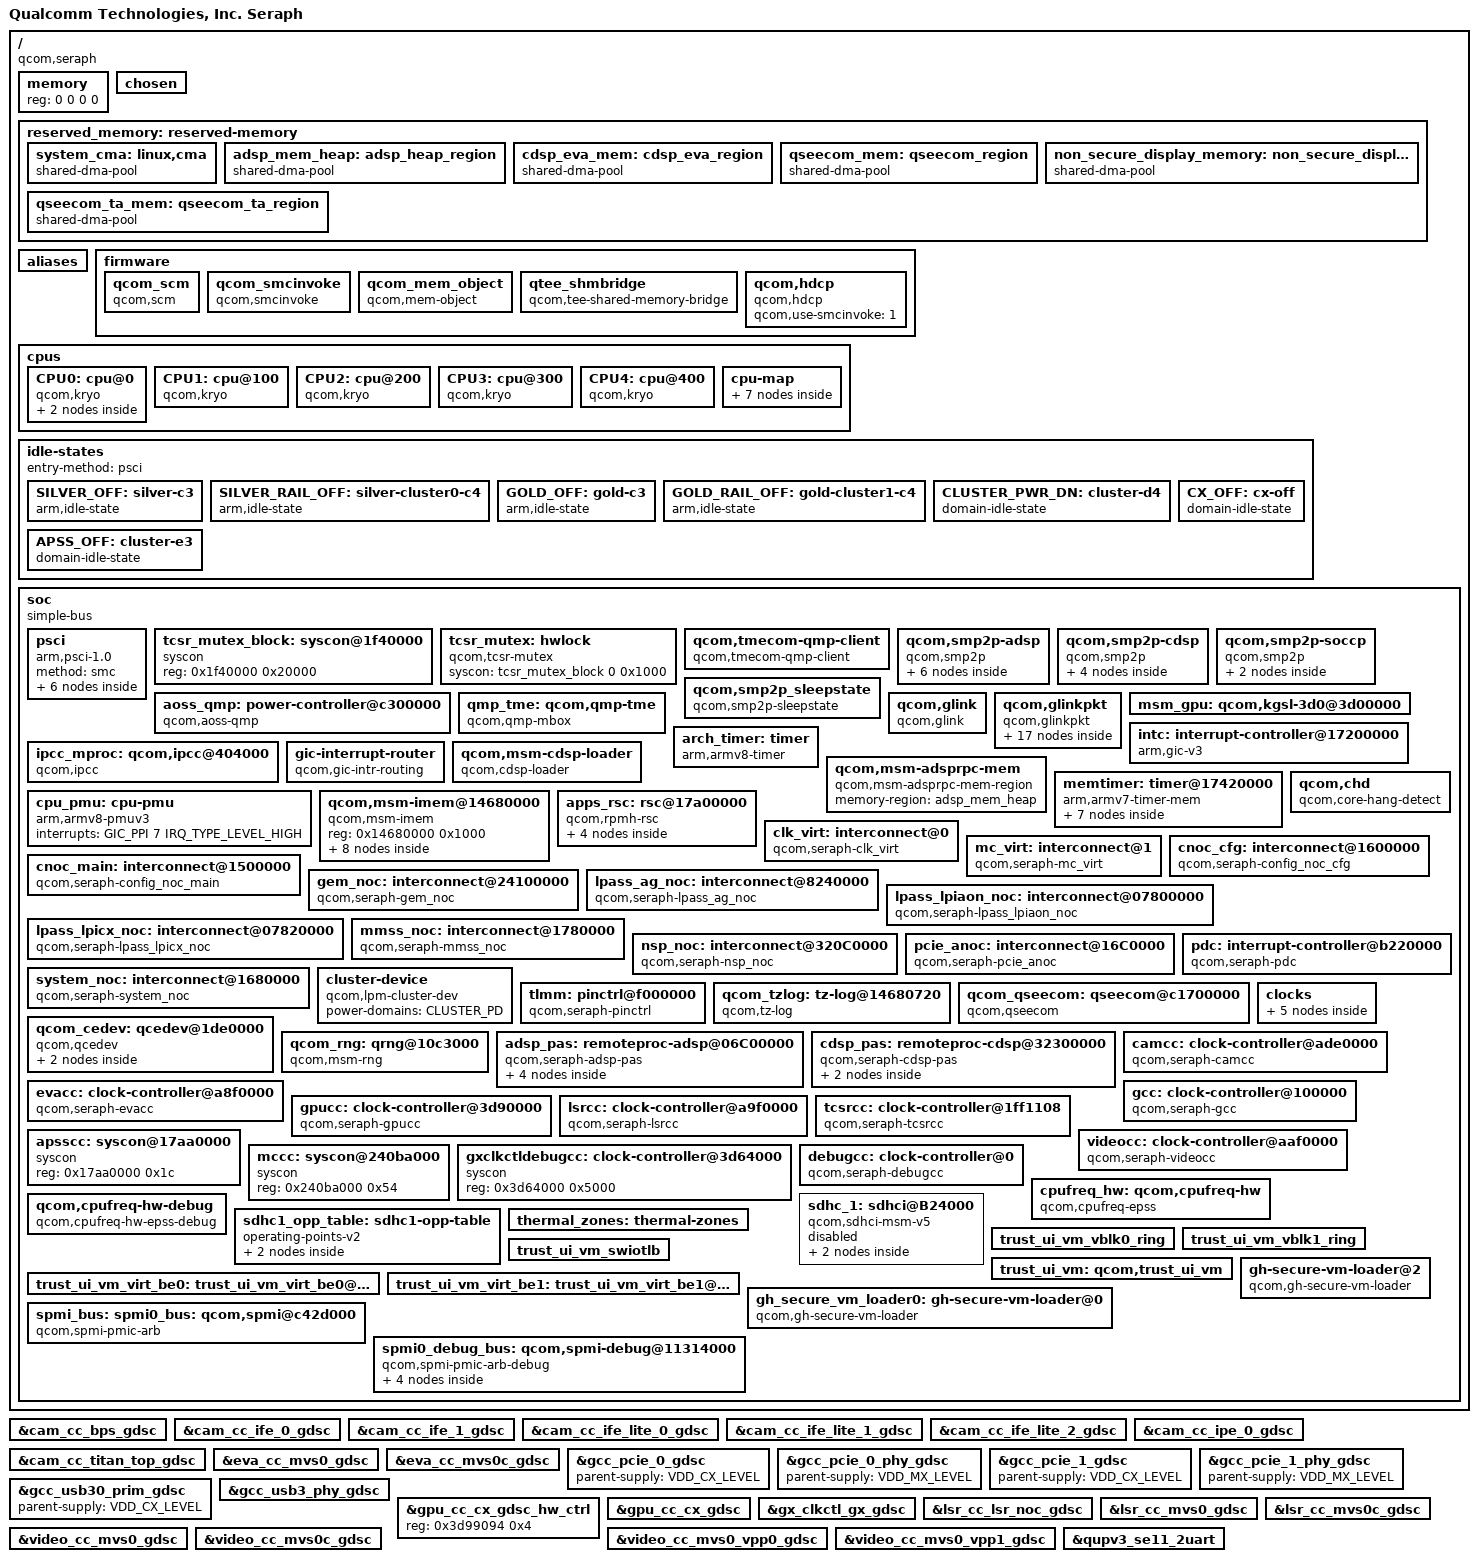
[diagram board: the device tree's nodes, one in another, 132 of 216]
#include <dt-bindings/interrupt-controller/arm-gic.h>
#include <dt-bindings/soc/qcom,rpmh-rsc.h>
#include <dt-bindings/clock/qcom,rpmh.h>
#include <dt-bindings/clock/qcom,camcc-seraph.h>
#include <dt-bindings/clock/qcom,evacc-seraph.h>
#include <dt-bindings/clock/qcom,gcc-seraph.h>
#include <dt-bindings/clock/qcom,gpucc-seraph.h>
#include <dt-bindings/clock/qcom,lsrcc-seraph.h>
#include <dt-bindings/clock/qcom,tcsrcc-seraph.h>
#include <dt-bindings/clock/qcom,videocc-seraph.h>
#include <dt-bindings/interconnect/qcom,seraph.h>
#include <dt-bindings/mailbox/qcom-ipcc.h>
#include <dt-bindings/regulator/qcom,rpmh-regulator-levels.h>
#include <dt-bindings/spmi/spmi.h>

/ {
	model = "Qualcomm Technologies, Inc. Seraph";
	compatible = "qcom,seraph";
	qcom,msm-id = <672 0x10000>;
	interrupt-parent = <&intc>;

	#address-cells = <2>;
	#size-cells = <2>;
	memory { device_type = "memory"; reg = <0 0 0 0>; };

	chosen: chosen {
		bootargs = "kpti=0 log_buf_len=256K swiotlb=0 loop.max_part=7 loglevel=8 cpufreq.default_governor=performance";
	};

	reserved_memory: reserved-memory {};

	aliases {
		serial0 = &qupv3_se11_2uart;
		hsuart0 = &qupv3_se7_4uart;
		hsuart1 = &qupv3_se3_2uart;
		i2c0 = &qupv3_se0_i2c;
		i2c1 = &qupv3_se1_i2c;
		i2c2 = &qupv3_se2_i2c;
		i2c3 = &qupv3_se3_i2c;
		i2c4 = &qupv3_se4_i2c;
		i2c5 = &qupv3_se5_i2c;
		i2c6 = &qupv3_se6_i2c;
		i2c8 = &qupv3_se8_i2c;
		i2c9 = &qupv3_se9_i2c;
		i2c10 = &qupv3_se10_i2c;
		spi0 = &qupv3_se0_spi;
		spi1 = &qupv3_se1_spi;
		spi2 = &qupv3_se2_spi;
		spi3 = &qupv3_se3_spi;
		spi4 = &qupv3_se4_spi;
		spi5 = &qupv3_se5_spi;
		spi6 = &qupv3_se6_spi;
		spi7 = &qupv3_se7_spi;
		spi8 = &qupv3_se8_spi;
		spi9 = &qupv3_se9_spi;
		spi10 = &qupv3_se10_spi;
		mmc0 = &sdhc_1; /* SDC1 eMMC slot */
	 };

	firmware: firmware {};

	cpus {
		#address-cells = <2>;
		#size-cells = <0>;

		CPU0: cpu@0 {
			device_type = "cpu";
			compatible = "qcom,kryo";
			reg = <0x0 0x0>;
			enable-method = "psci";
			cpu-idle-states = <&SILVER_OFF &SILVER_RAIL_OFF>;
			power-domains = <&CPU_PD0>;
			power-domain-names = "psci";
			next-level-cache = <&L2_0>;
			capacity-dmips-mhz = <1024>;
			dynamic-power-coefficient = <100>;
			qcom,freq-domain = <&cpufreq_hw 0>;
			L2_0: l2-cache {
				compatible = "arm,arch-cache";
				cache-level = <2>;
				next-level-cache = <&L3_0>;

				L3_0: l3-cache {
					compatible = "arm,arch-cache";
					cache-level = <3>;
				};
			};
		};

		CPU1: cpu@100 {
			device_type = "cpu";
			compatible = "qcom,kryo";
			reg = <0x0 0x100>;
			enable-method = "psci";
			cpu-idle-states = <&SILVER_OFF &SILVER_RAIL_OFF>;
			power-domains = <&CPU_PD1>;
			power-domain-names = "psci";
			next-level-cache = <&L2_0>;
			capacity-dmips-mhz = <1024>;
			dynamic-power-coefficient = <100>;
			qcom,freq-domain = <&cpufreq_hw 0>;
		};

		CPU2: cpu@200 {
			device_type = "cpu";
			compatible = "qcom,kryo";
			reg = <0x0 0x200>;
			enable-method = "psci";
			cpu-idle-states = <&SILVER_OFF &SILVER_RAIL_OFF>;
			power-domains = <&CPU_PD2>;
			power-domain-names = "psci";
			next-level-cache = <&L2_0>;
			capacity-dmips-mhz = <1024>;
			dynamic-power-coefficient = <100>;
			qcom,freq-domain = <&cpufreq_hw 0>;
		};

		CPU3: cpu@300 {
			device_type = "cpu";
			compatible = "qcom,kryo";
			reg = <0x0 0x300>;
			enable-method = "psci";
			cpu-idle-states = <&SILVER_OFF &SILVER_RAIL_OFF>;
			power-domains = <&CPU_PD3>;
			power-domain-names = "psci";
			next-level-cache = <&L2_0>;
			capacity-dmips-mhz = <1024>;
			dynamic-power-coefficient = <100>;
			qcom,freq-domain = <&cpufreq_hw 0>;
		};

		CPU4: cpu@400 {
			device_type = "cpu";
			compatible = "qcom,kryo";
			reg = <0x0 0x400>;
			enable-method = "psci";
			cpu-idle-states = <&GOLD_OFF &GOLD_RAIL_OFF>;
			power-domains = <&CPU_PD4>;
			power-domain-names = "psci";
			next-level-cache = <&L2_0>;
			capacity-dmips-mhz = <1956>;
			dynamic-power-coefficient = <389>;
			qcom,freq-domain = <&cpufreq_hw 1>;
		};

		cpu-map {
			cluster0 {
				core0 {
					cpu = <&CPU0>;
				};

				core1 {
					cpu = <&CPU1>;
				};

				core2 {
					cpu = <&CPU2>;
				};

				core3 {
					cpu = <&CPU3>;
				};
			};

			cluster1 {
				core0 {
					cpu = <&CPU4>;
				};
			};
		};
	};

	idle-states {
		entry-method = "psci";

		SILVER_OFF: silver-c3 {  /* C3 */
			compatible = "arm,idle-state";
			idle-state-name = "pc";
			entry-latency-us = <250>;
			exit-latency-us = <900>;
			min-residency-us = <3200>;
			arm,psci-suspend-param = <0x40000003>;
			local-timer-stop;
		};

		SILVER_RAIL_OFF: silver-cluster0-c4 { /* C4 */
			compatible = "arm,idle-state";
			idle-state-name = "rail-pc";
			entry-latency-us = <550>;
			exit-latency-us = <750>;
			min-residency-us = <6700>;
			arm,psci-suspend-param = <0x40000004>;
			local-timer-stop;
		};

		GOLD_OFF: gold-c3 {  /* C3 */
			compatible = "arm,idle-state";
			idle-state-name = "pc";
			entry-latency-us = <400>;
			exit-latency-us = <1100>;
			min-residency-us = <4011>;
			arm,psci-suspend-param = <0x40000003>;
			local-timer-stop;
		};

		GOLD_RAIL_OFF: gold-cluster1-c4 { /* C4 */
			compatible = "arm,idle-state";
			idle-state-name = "rail-pc";
			entry-latency-us = <550>;
			exit-latency-us = <1050>;
			min-residency-us = <7951>;
			arm,psci-suspend-param = <0x40000004>;
			local-timer-stop;
		};

		CLUSTER_PWR_DN: cluster-d4 { /* D4 */
			compatible = "domain-idle-state";
			idle-state-name = "l3-off";
			entry-latency-us = <750>;
			exit-latency-us = <2350>;
			min-residency-us = <9144>;
			arm,psci-suspend-param = <0x41000044>;
		};

		CX_OFF: cx-off { /* Cx Off */
			compatible = "domain-idle-state";
			idle-state-name = "cx-ret";
			entry-latency-us = <1561>;
			exit-latency-us = <2801>;
			min-residency-us = <8550>;
			arm,psci-suspend-param = <0x41002344>;
		};

		APSS_OFF: cluster-e3 { /* E3 */
			compatible = "domain-idle-state";
			idle-state-name = "llcc-off";
			entry-latency-us = <2800>;
			exit-latency-us = <4400>;
			min-residency-us = <10150>;
			arm,psci-suspend-param = <0x4100c344>;
		};
	};

	soc: soc { };

};

&soc {
	#address-cells = <1>;
	#size-cells = <1>;

	ranges = <0 0 0 0xffffffff>;
	compatible = "simple-bus";

	psci {
		compatible = "arm,psci-1.0";
		method = "smc";

		CPU_PD0: cpu-pd0 {
			#power-domain-cells = <0>;
			power-domains = <&CLUSTER_PD>;
		};

		CPU_PD1: cpu-pd1 {
			#power-domain-cells = <0>;
			power-domains = <&CLUSTER_PD>;
		};

		CPU_PD2: cpu-pd2 {
			#power-domain-cells = <0>;
			power-domains = <&CLUSTER_PD>;
		};

		CPU_PD3: cpu-pd3 {
			#power-domain-cells = <0>;
			power-domains = <&CLUSTER_PD>;
		};

		CPU_PD4: cpu-pd4 {
			#power-domain-cells = <0>;
			power-domains = <&CLUSTER_PD>;
		};

		CLUSTER_PD: cluster-pd {
			#power-domain-cells = <0>;
			domain-idle-states = <&CLUSTER_PWR_DN &CX_OFF &APSS_OFF>;
		};
	};

	tcsr_mutex_block: syscon@1f40000 {
		compatible = "syscon";
		reg = <0x1f40000 0x20000>;
	};

	tcsr_mutex: hwlock {
		compatible = "qcom,tcsr-mutex";
		syscon = <&tcsr_mutex_block 0 0x1000>;
		#hwlock-cells = <1>;
	};

	qcom,tmecom-qmp-client {
		compatible = "qcom,tmecom-qmp-client";
		mboxes = <&qmp_tme 0>;
		mbox-names = "tmecom";
		label = "tmecom";
		depends-on-supply = <&qmp_tme>;
	};

	qcom,smp2p-adsp {
		compatible = "qcom,smp2p";
		qcom,smem = <443>, <429>;
		interrupt-parent = <&ipcc_mproc>;
		interrupts = <IPCC_CLIENT_LPASS IPCC_MPROC_SIGNAL_SMP2P
			      IRQ_TYPE_EDGE_RISING>;
		mboxes = <&ipcc_mproc IPCC_CLIENT_LPASS
			  IPCC_MPROC_SIGNAL_SMP2P>;
		qcom,local-pid = <0>;
		qcom,remote-pid = <2>;

		adsp_smp2p_out: master-kernel {
			qcom,entry-name = "master-kernel";
			#qcom,smem-state-cells = <1>;
		};

		adsp_smp2p_in: slave-kernel {
			qcom,entry-name = "slave-kernel";
			interrupt-controller;
			#interrupt-cells = <2>;
		};

		sleepstate_smp2p_out: sleepstate-out {
			qcom,entry-name = "sleepstate";
			#qcom,smem-state-cells = <1>;
		};

		sleepstate_smp2p_in: qcom,sleepstate-in {
			qcom,entry-name = "sleepstate_see";
			interrupt-controller;
			#interrupt-cells = <2>;
		};

		smp2p_rdbg2_out: qcom,smp2p-rdbg2-out {
			qcom,entry-name = "rdbg";
			#qcom,smem-state-cells = <1>;
		};

		smp2p_rdbg2_in: qcom,smp2p-rdbg2-in {
			qcom,entry-name = "rdbg";
			interrupt-controller;
			#interrupt-cells = <2>;
		};
	};

	qcom,smp2p-cdsp {
		compatible = "qcom,smp2p";
		qcom,smem = <94>, <432>;
		interrupt-parent = <&ipcc_mproc>;
		interrupts = <IPCC_CLIENT_CDSP IPCC_MPROC_SIGNAL_SMP2P
			      IRQ_TYPE_EDGE_RISING>;
		mboxes = <&ipcc_mproc IPCC_CLIENT_CDSP IPCC_MPROC_SIGNAL_SMP2P>;
		qcom,local-pid = <0>;
		qcom,remote-pid = <5>;

		cdsp_smp2p_out: master-kernel {
			qcom,entry-name = "master-kernel";
			#qcom,smem-state-cells = <1>;
		};

		cdsp_smp2p_in: slave-kernel {
			qcom,entry-name = "slave-kernel";
			interrupt-controller;
			#interrupt-cells = <2>;
		};

		smp2p_rdbg5_out: qcom,smp2p-rdbg5-out {
			qcom,entry-name = "rdbg";
			#qcom,smem-state-cells = <1>;
		};

		smp2p_rdbg5_in: qcom,smp2p-rdbg5-in {
			qcom,entry-name = "rdbg";
			interrupt-controller;
			#interrupt-cells = <2>;
		};
	};

	qcom,smp2p-soccp {
		compatible = "qcom,smp2p";
		qcom,smem = <617>, <616>;
		interrupt-parent = <&ipcc_mproc>;
		interrupts = <IPCC_CLIENT_SOCCP IPCC_MPROC_SIGNAL_SMP2P
			      IRQ_TYPE_EDGE_RISING>;
		mboxes = <&ipcc_mproc IPCC_CLIENT_SOCCP IPCC_MPROC_SIGNAL_SMP2P>;
		qcom,local-pid = <0>;
		qcom,remote-pid = <19>;

		soccp_smp2p_out: master-kernel {
			qcom,entry-name = "master-kernel";
			#qcom,smem-state-cells = <1>;
		};

		soccp_smp2p_in: slave-kernel {
			qcom,entry-name = "slave-kernel";
			interrupt-controller;
			#interrupt-cells = <2>;
		};
	};

	qcom,smp2p_sleepstate {
		compatible = "qcom,smp2p-sleepstate";
		qcom,smem-states = <&sleepstate_smp2p_out 0>;
		interrupt-parent = <&sleepstate_smp2p_in>;
		interrupts = <0 0>;
		interrupt-names = "smp2p-sleepstate-in";
	};

	aoss_qmp: power-controller@c300000 {
		compatible = "qcom,aoss-qmp";
		reg = <0xc300000 0x400>;
		interrupt-parent = <&ipcc_mproc>;
		interrupts = <IPCC_CLIENT_AOP
			      IPCC_MPROC_SIGNAL_GLINK_QMP
			      IRQ_TYPE_EDGE_RISING>;
		mboxes = <&ipcc_mproc IPCC_CLIENT_AOP
			  IPCC_MPROC_SIGNAL_GLINK_QMP>;

		#power-domain-cells = <1>;
		#clock-cells = <0>;
	};

	qmp_tme: qcom,qmp-tme {
		compatible = "qcom,qmp-mbox";
		qcom,remote-pid = <14>;
		mboxes = <&ipcc_mproc IPCC_CLIENT_TME
			  IPCC_MPROC_SIGNAL_GLINK_QMP>;
		mbox-names = "tme_qmp";
		interrupt-parent = <&ipcc_mproc>;
		interrupts = <IPCC_CLIENT_TME
			      IPCC_MPROC_SIGNAL_GLINK_QMP
			      IRQ_TYPE_EDGE_RISING>;

		label = "tme";
		qcom,early-boot;
		priority = <0>;
		mbox-desc-offset = <0x0>;
		#mbox-cells = <1>;
	};

	qcom,glink {
		compatible = "qcom,glink";
	};

	qcom,glinkpkt {
		compatible = "qcom,glinkpkt";

		qcom,glinkpkt-at-mdm0 {
			qcom,glinkpkt-edge = "mpss";
			qcom,glinkpkt-ch-name = "DS";
			qcom,glinkpkt-dev-name = "at_mdm0";
		};

		qcom,glinkpkt-ctrl-cdsp {
			qcom,glinkpkt-edge = "cdsp";
			qcom,glinkpkt-ch-name = "LOOPBACK_CTL_CDSP";
			qcom,glinkpkt-dev-name = "glink_pkt_ctrl_cdsp";
		};

		qcom,glinkpkt-data-cdsp {
			qcom,glinkpkt-edge = "cdsp";
			qcom,glinkpkt-ch-name = "LOOPBACK_DATA_CDSP";
			qcom,glinkpkt-dev-name = "glink_pkt_data_cdsp";
		};

		qcom,glinkpkt-ctrl-lpass {
			qcom,glinkpkt-edge = "lpass";
			qcom,glinkpkt-ch-name = "LOOPBACK_CTL_LPASS";
			qcom,glinkpkt-dev-name = "glink_pkt_ctrl_lpass";
		};

		qcom,glinkpkt-data-lpass {
			qcom,glinkpkt-edge = "lpass";
			qcom,glinkpkt-ch-name = "LOOPBACK_DATA_LPASS";
			qcom,glinkpkt-dev-name = "glink_pkt_data_lpass";
		};

		qcom,glinkpkt-ctrl-mpss {
			qcom,glinkpkt-edge = "mpss";
			qcom,glinkpkt-ch-name = "LOOPBACK_CTL_MPSS";
			qcom,glinkpkt-dev-name = "glink_pkt_ctrl_mpss";
		};

		qcom,glinkpkt-data-mpss {
			qcom,glinkpkt-edge = "mpss";
			qcom,glinkpkt-ch-name = "LOOPBACK_DATA_MPSS";
			qcom,glinkpkt-dev-name = "glink_pkt_data_mpss";
		};

		qcom,glinkpkt-apr-apps2 {
			qcom,glinkpkt-edge = "adsp";
			qcom,glinkpkt-ch-name = "apr_apps2";
			qcom,glinkpkt-dev-name = "apr_apps2";
		};

		qcom,glinkpkt-data40-cntl {
			qcom,glinkpkt-edge = "mpss";
			qcom,glinkpkt-ch-name = "DATA40_CNTL";
			qcom,glinkpkt-dev-name = "smdcntl8";
		};

		qcom,glinkpkt-data1 {
			qcom,glinkpkt-edge = "mpss";
			qcom,glinkpkt-ch-name = "DATA1";
			qcom,glinkpkt-dev-name = "smd7";
		};

		qcom,glinkpkt-data4 {
			qcom,glinkpkt-edge = "mpss";
			qcom,glinkpkt-ch-name = "DATA4";
			qcom,glinkpkt-dev-name = "smd8";
		};

		qcom,glinkpkt-data11 {
			qcom,glinkpkt-edge = "mpss";
			qcom,glinkpkt-ch-name = "DATA11";
			qcom,glinkpkt-dev-name = "smd11";
		};

		qcom,glinkpkt-qmc-dma {
			qcom,glinkpkt-edge = "mpss";
			qcom,glinkpkt-ch-name = "QMC_DMA_LINE";
			qcom,glinkpkt-dev-name = "qmc_dma";
			qcom,glinkpkt-enable-ch-close;
		};

		qcom,glinkpkt-qmc-cma {
			qcom,glinkpkt-edge = "mpss";
			qcom,glinkpkt-ch-name = "QMC_CMA_LINE";
			qcom,glinkpkt-dev-name = "qmc_cma";
			qcom,glinkpkt-enable-ch-close;
		};

		qcom,glinkpkt-ims-sub-1 {
			qcom,glinkpkt-edge = "mpss";
			qcom,glinkpkt-ch-name = "Ims_dc_sub1";
			qcom,glinkpkt-dev-name = "ims_dc_sub1";
			qcom,glinkpkt-enable-ch-close;
		};

		qcom,glinkpkt-ims-sub-2 {
			qcom,glinkpkt-edge = "mpss";
			qcom,glinkpkt-ch-name = "Ims_dc_sub2";
			qcom,glinkpkt-dev-name = "ims_dc_sub2";
			qcom,glinkpkt-enable-ch-close;
		};

		qcom,glinkpkt-xpan_control {
			qcom,glinkpkt-edge = "adsp";
			qcom,glinkpkt-ch-name = "bt_cp_ctrl";
			qcom,glinkpkt-dev-name = "bt_cp_ctrl";
		};
	};

	msm_gpu: qcom,kgsl-3d0@3d00000 { };

	intc: interrupt-controller@17200000 {
		compatible = "arm,gic-v3";
		#interrupt-cells = <3>;
		interrupt-controller;
		#redistributor-regions = <1>;
		redistributor-stride = <0x0 0x20000>;
		reg = <0x17200000 0x10000>,       /* GICD */
		     <0x17260000 0xA0000>;       /* GICR * 5 */
		interrupts = <GIC_PPI 9 IRQ_TYPE_LEVEL_HIGH>;
	};

	arch_timer: timer {
		compatible = "arm,armv8-timer";
		interrupts = <GIC_PPI 13 (GIC_CPU_MASK_SIMPLE(8) | IRQ_TYPE_LEVEL_LOW)>,
			     <GIC_PPI 14 (GIC_CPU_MASK_SIMPLE(8) | IRQ_TYPE_LEVEL_LOW)>,
			     <GIC_PPI 11 (GIC_CPU_MASK_SIMPLE(8) | IRQ_TYPE_LEVEL_LOW)>,
			     <GIC_PPI 12 (GIC_CPU_MASK_SIMPLE(8) | IRQ_TYPE_LEVEL_LOW)>;
		clock-frequency = <19200000>;
	};

	ipcc_mproc: qcom,ipcc@404000 {
		compatible = "qcom,ipcc";
		reg = <0x404000 0x1000>;
		interrupts = <GIC_SPI 229 IRQ_TYPE_LEVEL_HIGH>;
		interrupt-controller;
		#interrupt-cells = <3>;
		#mbox-cells = <2>;
	};

	gic-interrupt-router {
		compatible = "qcom,gic-intr-routing";
		qcom,gic-class0-cpus = <&CPU0 &CPU1 &CPU2 &CPU3>;
		qcom,gic-class1-cpus = <&CPU4>;
	};

	qcom,msm-cdsp-loader {
		compatible = "qcom,cdsp-loader";
		qcom,proc-img-to-load = "cdsp";
		qcom,rproc-handle = <&cdsp_pas>;
	};

	qcom,msm-adsprpc-mem {
		compatible = "qcom,msm-adsprpc-mem-region";
		memory-region = <&adsp_mem_heap>;
	};

	memtimer: timer@17420000 {
		#address-cells = <1>;
		#size-cells = <1>;
		ranges;
		compatible = "arm,armv7-timer-mem";
		reg = <0x17420000 0x1000>;
		clock-frequency = <19200000>;

		frame@17421000 {
			frame-number = <0>;
			interrupts = <GIC_SPI 8 IRQ_TYPE_LEVEL_HIGH>,
				     <GIC_SPI 6 IRQ_TYPE_LEVEL_HIGH>;
			reg = <0x17421000 0x1000>,
			      <0x17422000 0x1000>;
		};

		frame@17423000 {
			frame-number = <1>;
			interrupts = <GIC_SPI 9 IRQ_TYPE_LEVEL_HIGH>;
			reg = <0x17423000 0x1000>;
			status = "disabled";
		};

		frame@17425000 {
			frame-number = <2>;
			interrupts = <GIC_SPI 10 IRQ_TYPE_LEVEL_HIGH>;
			reg = <0x17425000 0x1000>;
			status = "disabled";
		};

		frame@17427000 {
			frame-number = <3>;
			interrupts = <GIC_SPI 11 IRQ_TYPE_LEVEL_HIGH>;
			reg = <0x17427000 0x1000>;
			status = "disabled";
		};

		frame@17429000 {
			frame-number = <4>;
			interrupts = <GIC_SPI 12 IRQ_TYPE_LEVEL_HIGH>;
			reg = <0x17429000 0x1000>;
			status = "disabled";
		};

		frame@1742b000 {
			frame-number = <5>;
			interrupts = <GIC_SPI 13 IRQ_TYPE_LEVEL_HIGH>;
			reg = <0x1742b000 0x1000>;
			status = "disabled";
		};

		frame@1742d000 {
			frame-number = <6>;
			interrupts = <GIC_SPI 14 IRQ_TYPE_LEVEL_HIGH>;
			reg = <0x1742d000 0x1000>;
			status = "disabled";
		};
	};

	cpu_pmu: cpu-pmu {
		compatible = "arm,armv8-pmuv3";
		interrupts = <GIC_PPI 7 IRQ_TYPE_LEVEL_HIGH>;
	};

	qcom,msm-imem@14680000 {
		compatible = "qcom,msm-imem";
		reg = <0x14680000 0x1000>;
		ranges = <0x0 0x14680000 0x1000>;
		#address-cells = <1>;
		#size-cells = <1>;

		mem_dump_table@10 {
			compatible = "qcom,msm-imem-mem_dump_table";
			reg = <0x10 0x8>;
		};

		restart_reason@65c {
			compatible = "qcom,msm-imem-restart_reason";
			reg = <0x65c 0x4>;
		};

		dload_type@1c {
			compatible = "qcom,msm-imem-dload-type";
			reg = <0x1c 0x4>;
		};

		boot_stats@6b0 {
			compatible = "qcom,msm-imem-boot_stats";
			reg = <0x6b0 0x20>;
		};

		kaslr_offset@6d0 {
			compatible = "qcom,msm-imem-kaslr_offset";
			reg = <0x6d0 0xc>;
		};

		pil@94c {
			compatible = "qcom,pil-reloc-info";
			reg = <0x94c 0xc8>;
		};

		pil@6dc {
			compatible = "qcom,msm-imem-pil-disable-timeout";
			reg = <0x6dc 0x4>;
		};

		diag_dload@c8 {
			compatible = "qcom,msm-imem-diag-dload";
			reg = <0xc8 0xc8>;
		};

	};

	qcom,chd {
		compatible = "qcom,core-hang-detect";
		label = "core";
		qcom,chd-percpu-info = <&CPU0 0x17800058 0x17800060>,
					<&CPU1 0x17810058 0x17810060>,
					<&CPU2 0x17820058 0x17820060>,
					<&CPU3 0x17830058 0x17830060>,
					<&CPU4 0x17840058 0x17840060>;
	};

	apps_rsc: rsc@17a00000 {
		label = "apps_rsc";
		compatible = "qcom,rpmh-rsc";
		reg = <0x17a00000 0x10000>,
		      <0x17a10000 0x10000>,
		      <0x17a20000 0x10000>;
		reg-names = "drv-0", "drv-1", "drv-2";
		qcom,drv-count = <3>;
		interrupts = <GIC_SPI 3 IRQ_TYPE_LEVEL_HIGH>,
			     <GIC_SPI 4 IRQ_TYPE_LEVEL_HIGH>,
			     <GIC_SPI 5 IRQ_TYPE_LEVEL_HIGH>;
		power-domains = <&CLUSTER_PD>;

		apps_rsc_drv2: drv@2 {
			qcom,drv-id = <2>;
			qcom,tcs-offset = <0xd00>;
			qcom,tcs-distance = <0x2a0>;
			channel@0 {
				qcom,tcs-config = <ACTIVE_TCS    3>,
						  <SLEEP_TCS     2>,
						  <WAKE_TCS      2>,
						  <CONTROL_TCS   0>,
						  <FAST_PATH_TCS 1>;
			};

			apps_bcm_voter: bcm_voter {
				compatible = "qcom,bcm-voter";
			};

			rpmhcc: clock-controller {
				compatible = "qcom,seraph-rpmh-clk";
				#clock-cells = <1>;
			};
		};
	};

	clk_virt: interconnect@0 {
		compatible = "qcom,seraph-clk_virt";
		#interconnect-cells = <1>;
		qcom,bcm-voter-names = "hlos";
		qcom,bcm-voters = <&apps_bcm_voter>;
	};

	mc_virt: interconnect@1 {
		compatible = "qcom,seraph-mc_virt";
		#interconnect-cells = <1>;
		qcom,bcm-voter-names = "hlos";
		qcom,bcm-voters = <&apps_bcm_voter>;
	};

	cnoc_cfg: interconnect@1600000 {
		compatible = "qcom,seraph-config_noc_cfg";
		reg = <0x01600000 0x7200>;
		#interconnect-cells = <1>;
		qcom,bcm-voter-names = "hlos";
		qcom,bcm-voters = <&apps_bcm_voter>;
		qcom,skip-qos;
	};

	cnoc_main: interconnect@1500000 {
		compatible = "qcom,seraph-config_noc_main";
		reg = <0x01500000 0x1a200>;
		#interconnect-cells = <1>;
		qcom,bcm-voter-names = "hlos";
		qcom,bcm-voters = <&apps_bcm_voter>;
		qcom,skip-qos;
	};

	gem_noc: interconnect@24100000 {
		compatible = "qcom,seraph-gem_noc";
		reg = <0x24100000 0x163080>;
		#interconnect-cells = <1>;
		qcom,bcm-voter-names = "hlos";
		qcom,bcm-voters = <&apps_bcm_voter>;
		qcom,skip-qos;
	};

	lpass_ag_noc: interconnect@8240000 {
		compatible = "qcom,seraph-lpass_ag_noc";
		reg = <0x08240000 0xe080>;
		#interconnect-cells = <1>;
		qcom,bcm-voter-names = "hlos";
		qcom,bcm-voters = <&apps_bcm_voter>;
		qcom,skip-qos;
	};

	lpass_lpiaon_noc: interconnect@07800000 {
		compatible = "qcom,seraph-lpass_lpiaon_noc";
		reg = <0x07800000 0x19080>;
		#interconnect-cells = <1>;
		qcom,bcm-voter-names = "hlos";
		qcom,bcm-voters = <&apps_bcm_voter>;
		qcom,skip-qos;
	};

	lpass_lpicx_noc: interconnect@07820000 {
		compatible = "qcom,seraph-lpass_lpicx_noc";
		reg = <0x07820000 0x44080>;
		#interconnect-cells = <1>;
		qcom,bcm-voter-names = "hlos";
		qcom,bcm-voters = <&apps_bcm_voter>;
		qcom,skip-qos;
	};

	mmss_noc: interconnect@1780000 {
		compatible = "qcom,seraph-mmss_noc";
		reg = <0x01780000 0x6b800>;
		#interconnect-cells = <1>;
		qcom,bcm-voter-names = "hlos";
		qcom,bcm-voters = <&apps_bcm_voter>;
		qcom,skip-qos;
	};

	nsp_noc: interconnect@320C0000 {
		compatible = "qcom,seraph-nsp_noc";
		reg = <0x320C0000 0x1f400>;
		#interconnect-cells = <1>;
		qcom,bcm-voter-names = "hlos";
		qcom,bcm-voters = <&apps_bcm_voter>;
		qcom,skip-qos;
	};

	pcie_anoc: interconnect@16C0000 {
		compatible = "qcom,seraph-pcie_anoc";
		reg = <0x016C0000 0xe400>;
		#interconnect-cells = <1>;
		qcom,bcm-voter-names = "hlos";
		qcom,bcm-voters = <&apps_bcm_voter>;
		qcom,skip-qos;
	};

	system_noc: interconnect@1680000 {
		compatible = "qcom,seraph-system_noc";
		reg = <0x01680000 0x2d800>;
		#interconnect-cells = <1>;
		qcom,bcm-voter-names = "hlos";
		qcom,bcm-voters = <&apps_bcm_voter>;
		qcom,skip-qos;
	};

	pdc: interrupt-controller@b220000 {
		compatible = "qcom,seraph-pdc", "qcom,pdc";
		reg = <0xb220000 0x10000>, <0x174000f0 0x64>;
		qcom,pdc-ranges = <0 221 1>, <1 227 2>, <3 238 4>,
				  <8 263 2>, <10 293 3>, <14 297 2>,
				  <16 348 2>, <18 351 3>, <22 355 2>,
				  <24 641 1>, <25 358 1>, <26 376 2>,
				  <28 443 1>, <30 242 1>, <31 296 1>,
				  <32 354 1>, <33 357 1>, <34 444 3>,
				  <37 472 1>, <40 447 1>, <41 461 1>,
				  <42 473 1>, <43 462 1>, <44 584 1>,
				  <45 586 1>, <47 607 2>, <49 642 1>,
				  <50 656 1>, <51 527 1>, <61 505 1>,
				  <62 605 1>, <63 372 2>, <65 378 1>,
				  <66 431 1>, <70 528 46>, <116 609 31>,
				  <147 63 1>, <148 716 12>, <160 251 5>,
				  <165 379 1>;
		#interrupt-cells = <2>;
		interrupt-parent = <&intc>;
		interrupt-controller;
	};

	cluster-device {
		compatible = "qcom,lpm-cluster-dev";
		power-domains = <&CLUSTER_PD>;
	};

	tlmm: pinctrl@f000000 {
		compatible = "qcom,seraph-pinctrl";
		reg = <0x0F000000 0x1000000>;
		interrupts = <GIC_SPI 208 IRQ_TYPE_LEVEL_HIGH>;
		gpio-controller;
		#gpio-cells = <2>;
		interrupt-controller;
		#interrupt-cells = <2>;
		wakeup-parent = <&pdc>;
	};

	qcom_tzlog: tz-log@14680720 {
		compatible = "qcom,tz-log";
		reg = <0x14680720 0x3000>;
		qcom,hyplog-enabled;
		hyplog-address-offset = <0x410>;
		hyplog-size-offset = <0x414>;
		tmecrashdump-address-offset = <0x81CA0000>;
	};

	qcom_qseecom: qseecom@c1700000 {
		compatible = "qcom,qseecom";
		memory-region = <&qseecom_mem>;
		qseecom_mem = <&qseecom_mem>;
		qseecom_ta_mem = <&qseecom_ta_mem>;
		qcom,no-user-contig-mem-support;
		qcom,hlos-num-ce-hw-instances = <1>;
		qcom,hlos-ce-hw-instance = <0>;
		qcom,qsee-ce-hw-instance = <0>;
		qcom,disk-encrypt-pipe-pair = <2>;
		qcom,no-clock-support;
		qcom,appsbl-qseecom-support;
		qcom,commonlib64-loaded-by-uefi;
		qcom,qsee-reentrancy-support = <2>;
	};

	qcom_cedev: qcedev@1de0000 {
		compatible = "qcom,qcedev";
		reg = <0x1de0000 0x20000>,
			<0x1dc4000 0x28000>;
		reg-names = "crypto-base","crypto-bam-base";
		interrupts = <GIC_SPI 272 IRQ_TYPE_LEVEL_HIGH>;
		qcom,bam-pipe-pair = <2>;
		qcom,offload-ops-support;
		qcom,bam-pipe-offload-cpb-hlos = <1>;
		qcom,bam-pipe-offload-hlos-cpb = <3>;
		qcom,bam-pipe-offload-hlos-cpb-1 = <8>;
		qcom,bam-pipe-offload-hlos-hlos = <4>;
		qcom,bam-pipe-offload-hlos-hlos-1 = <9>;
		qcom,ce-hw-instance = <0>;
		qcom,ce-device = <0>;
		qcom,ce-hw-shared;
		qcom,bam-ee = <0>;
		qcom,smmu-s1-enable;
		qcom,no-clock-support;
		interconnect-names = "data_path";
		interconnects = <&system_noc MASTER_CRYPTO &mc_virt SLAVE_EBI1>;
		iommus = <&apps_smmu 0x080 0x0>,
			<&apps_smmu 0x081 0x0>;
		qcom,iommu-dma = "atomic";
		dma-coherent;

		qcom_cedev_ns_cb {
			compatible = "qcom,qcedev,context-bank";
			label = "ns_context";
			iommus = <&apps_smmu 0x081 0x0>;
			dma-coherent;
		};

		qcom_cedev_s_cb {
			compatible = "qcom,qcedev,context-bank";
			label = "secure_context";
			iommus = <&apps_smmu 0x083 0x0>;
			qcom,iommu-vmid = <0x9>;
			qcom,secure-context-bank;
			dma-coherent;
		};
	};

	qcom_rng: qrng@10c3000 {
		compatible = "qcom,msm-rng";
		reg = <0x10c3000 0x1000>;
		qcom,no-qrng-config;
		qcom,no-clock-support;
	};

	adsp_pas: remoteproc-adsp@06C00000 {
		compatible = "qcom,seraph-adsp-pas";
		reg = <0x06C00000 0x10000>;
		status = "ok";

		cx-supply = <&VDD_LPI_CX_LEVEL>;
		cx-uV-uA = <RPMH_REGULATOR_LEVEL_TURBO 0>;
		mx-supply = <&VDD_LPI_MX_LEVEL>;
		mx-uV-uA = <RPMH_REGULATOR_LEVEL_TURBO 0>;
		reg-names = "cx", "mx";

		clocks = <&rpmhcc RPMH_CXO_CLK>;
		clock-names = "xo";

		qcom,signal-aop;
		qcom,qmp = <&aoss_qmp>;

		interconnects = <&lpass_lpicx_noc MASTER_LPASS_PROC &mc_virt SLAVE_EBI1>,
				<&system_noc MASTER_CRYPTO &mc_virt SLAVE_EBI1>;

		interconnect-names = "rproc_ddr", "crypto_ddr";

		memory-region = <&adsp_mem &q6_adsp_dtb_mem>;
		/* Inputs from ssc */
		interrupts-extended = <&pdc 6 IRQ_TYPE_EDGE_RISING>,
					<&adsp_smp2p_in 0 0>,
					<&adsp_smp2p_in 2 0>,
					<&adsp_smp2p_in 1 0>,
					<&adsp_smp2p_in 3 0>,
					<&adsp_smp2p_in 7 0>;

		interrupt-names = "wdog",
				"fatal",
				"handover",
				"ready",
				"stop-ack",
				"shutdown-ack";

		/* Outputs to turing */
		qcom,smem-states = <&adsp_smp2p_out 0>;
		qcom,smem-state-names = "stop";

		remoteproc_adsp_glink: glink-edge {
			qcom,remote-pid = <2>;
			transport = "smem";
			mboxes = <&ipcc_mproc IPCC_CLIENT_LPASS
				  IPCC_MPROC_SIGNAL_GLINK_QMP>;
			mbox-names = "adsp_smem";
			interrupt-parent = <&ipcc_mproc>;
			interrupts = <IPCC_CLIENT_LPASS
				      IPCC_MPROC_SIGNAL_GLINK_QMP
				      IRQ_TYPE_EDGE_RISING>;

			label = "adsp";
			qcom,glink-label = "lpass";

			qcom,adsp_qrtr {
				qcom,glink-channels = "IPCRTR";
				qcom,net-id = <2>;
				qcom,intents = <0x800  5
						0x2000 3
						0x4400 2>;

				qcom,no-wake-svc = <0x190>;
			};

			qcom,pmic_glink_rpmsg {
				qcom,glink-channels = "PMIC_RTR_ADSP_APPS";
			};

			qcom,pmic_glink_log_rpmsg {
				qcom,glink-channels = "PMIC_LOGS_ADSP_APPS";
				qcom,intents = <0x800 5
						0xc00 3
						0x2000 1>;
			};
		};
	};

	cdsp_pas: remoteproc-cdsp@32300000 {
		compatible = "qcom,seraph-cdsp-pas";
		reg = <0x32300000 0x10000>;
		status = "ok";
		cx-supply = <&VDD_CX_LEVEL>;
		cx-uV-uA = <RPMH_REGULATOR_LEVEL_TURBO 100000>;
		mx-supply = <&VDD_MX_LEVEL>;
		mx-uV-uA = <RPMH_REGULATOR_LEVEL_TURBO 100000>;
		nsp-supply = <&VDD_NSP_LEVEL>;
		nsp-uV-uA = <RPMH_REGULATOR_LEVEL_TURBO 100000>;
		reg-names = "cx","mx","nsp";

		firmware-name = "cdsp.mdt", "cdsp_dtb.mdt";
		memory-region = <&cdsp_mem &q6_cdsp_dtb_mem>;
		global-sync-mem-reg = <&global_sync_mem>;

		clocks = <&rpmhcc RPMH_CXO_CLK>;
		clock-names = "xo";

		qcom,signal-aop;
		qcom,qmp = <&aoss_qmp>;

		interconnects = <&nsp_noc MASTER_CDSP_PROC &mc_virt SLAVE_EBI1>,
				<&system_noc MASTER_CRYPTO &mc_virt SLAVE_EBI1>;
		interconnect-names = "rproc_ddr", "crypto_ddr";

		/* Inputs from turing */
		interrupts-extended = <&intc GIC_SPI 578 IRQ_TYPE_EDGE_RISING>,
					<&cdsp_smp2p_in 0 0>,
					<&cdsp_smp2p_in 2 0>,
					<&cdsp_smp2p_in 1 0>,
					<&cdsp_smp2p_in 3 0>;
		interrupt-names = "wdog",
				"fatal",
				"handover",
				"ready",
				"stop-ack";
		/* Outputs to turing */
		qcom,smem-states = <&cdsp_smp2p_out 0>;
		qcom,smem-state-names = "stop";

		remoteproc_cdsp_glink: glink-edge {
			qcom,remote-pid = <5>;
			transport = "smem";
			mboxes = <&ipcc_mproc IPCC_CLIENT_CDSP
				  IPCC_MPROC_SIGNAL_GLINK_QMP>;
			mbox-names = "cdsp_smem";
			interrupt-parent = <&ipcc_mproc>;
			interrupts = <IPCC_CLIENT_CDSP
				      IPCC_MPROC_SIGNAL_GLINK_QMP
				      IRQ_TYPE_EDGE_RISING>;

			label = "cdsp";
			qcom,glink-label = "cdsp";

			qcom,cdsp_qrtr {
				qcom,glink-channels = "IPCRTR";
				qcom,intents = <0x800  5
						0x2000 3
						0x4400 2>;
			};
		};
	};

	clocks {
		xo_board: xo_board {
			compatible = "fixed-clock";
			clock-frequency = <38400000>;
			clock-output-names = "xo_board";
			#clock-cells = <0>;
		};

		sleep_clk: sleep_clk {
			compatible = "fixed-clock";
			clock-frequency = <32000>;
			clock-output-names = "sleep_clk";
			#clock-cells = <0>;
		};

		pcie_0_pipe_clk: pcie_0_pipe_clk {
			compatible = "fixed-clock";
			clock-frequency = <1000>;
			clock-output-names = "pcie_0_pipe_clk";
			#clock-cells = <0>;
		};

		pcie_1_pipe_clk: pcie_1_pipe_clk {
			compatible = "fixed-clock";
			clock-frequency = <1000>;
			clock-output-names = "pcie_1_pipe_clk";
			#clock-cells = <0>;
		};

		usb3_phy_wrapper_gcc_usb30_pipe_clk: usb3_phy_wrapper_gcc_usb30_pipe_clk {
			compatible = "fixed-clock";
			clock-frequency = <1000>;
			clock-output-names = "usb3_phy_wrapper_gcc_usb30_pipe_clk";
			#clock-cells = <0>;
		};
	};

	camcc: clock-controller@ade0000 {
		compatible = "qcom,seraph-camcc", "syscon";
		reg = <0xade0000 0x20000>;
		reg-name = "cc_base";
		vdd_cx-supply = <&VDD_CX_LEVEL>;
		vdd_mx-supply = <&VDD_MX_LEVEL>;
		clocks = <&rpmhcc RPMH_CXO_CLK>,
			 <&sleep_clk>, <&gcc GCC_CAMERA_AHB_CLK>;
		clock-names = "bi_tcxo",
			      "sleep_clk", "iface";
		#clock-cells = <1>;
		#reset-cells = <1>;
	};

	evacc: clock-controller@a8f0000 {
		compatible = "qcom,seraph-evacc", "syscon";
		reg = <0xa8f0000 0x10000>;
		reg-name = "cc_base";
		vdd_mm-supply = <&VDD_MM_LEVEL>;
		vdd_mx-supply = <&VDD_MX_LEVEL>;
		clocks = <&rpmhcc RPMH_CXO_CLK>,
			 <&sleep_clk>, <&gcc GCC_EVA_AHB_CLK>;
		clock-names = "bi_tcxo",
			      "sleep_clk", "iface";
		#clock-cells = <1>;
		#reset-cells = <1>;
	};

	gcc: clock-controller@100000 {
		compatible = "qcom,seraph-gcc", "syscon";
		reg = <0x100000 0x1f4200>;
		reg-name = "cc_base";
		vdd_cx-supply = <&VDD_CX_LEVEL>;
		vdd_mx-supply = <&VDD_MX_LEVEL>;
		clocks = <&rpmhcc RPMH_CXO_CLK>,
			 <&pcie_0_pipe_clk>,
			 <&pcie_1_pipe_clk>,
			 <&sleep_clk>,
			 <&usb3_phy_wrapper_gcc_usb30_pipe_clk>;
		clock-names = "bi_tcxo",
			      "pcie_0_pipe_clk",
			      "pcie_1_pipe_clk",
			      "sleep_clk",
			      "usb3_phy_wrapper_gcc_usb30_pipe_clk";
		#clock-cells = <1>;
		#reset-cells = <1>;
	};

	gpucc: clock-controller@3d90000 {
		compatible = "qcom,seraph-gpucc", "syscon";
		reg = <0x3d90000 0x9800>;
		reg-name = "cc_base";
		vdd_cx-supply = <&VDD_CX_LEVEL>;
		vdd_mx-supply = <&VDD_MX_LEVEL>;
		clocks = <&rpmhcc RPMH_CXO_CLK>,
			 <&gcc GCC_GPU_GPLL0_CLK_SRC>,
			 <&gcc GCC_GPU_GPLL0_DIV_CLK_SRC>;
		clock-names = "bi_tcxo",
			      "gpll0_out_main",
			      "gpll0_out_main_div";
		#clock-cells = <1>;
		#reset-cells = <1>;
	};

	lsrcc: clock-controller@a9f0000 {
		compatible = "qcom,seraph-lsrcc", "syscon";
		reg = <0xa9f0000 0x10000>;
		reg-name = "cc_base";
		vdd_mm-supply = <&VDD_MM_LEVEL>;
		vdd_mx-supply = <&VDD_MX_LEVEL>;
		clocks = <&rpmhcc RPMH_CXO_CLK>,
			 <&sleep_clk>, <&gcc GCC_LSR_AHB_CLK>;
		clock-names = "bi_tcxo",
			      "sleep_clk", "iface";
		#clock-cells = <1>;
		#reset-cells = <1>;
	};

	tcsrcc: clock-controller@1ff1108 {
		compatible = "qcom,seraph-tcsrcc", "syscon";
		reg = <0x1ff1108 0x18>;
		reg-name = "cc_base";
		#clock-cells = <1>;
		#reset-cells = <1>;
	};

	videocc: clock-controller@aaf0000 {
		compatible = "qcom,seraph-videocc", "syscon";
		reg = <0xaaf0000 0x10000>;
		reg-name = "cc_base";
		vdd_mm-supply = <&VDD_MM_LEVEL>;
		vdd_mx-supply = <&VDD_MX_LEVEL>;
		clocks = <&rpmhcc RPMH_CXO_CLK>, <&gcc GCC_VIDEO_AHB_CLK>;
		clock-names = "bi_tcxo", "iface";
		#clock-cells = <1>;
		#reset-cells = <1>;
	};

	apsscc: syscon@17aa0000 {
		compatible = "syscon";
		reg = <0x17aa0000 0x1c>;
	};

	mccc: syscon@240ba000 {
		compatible = "syscon";
		reg = <0x240ba000 0x54>;
	};

	gxclkctldebugcc: clock-controller@3d64000 {
		compatible = "syscon";
		reg = <0x3d64000 0x5000>;
	};

	debugcc: clock-controller@0 {
		compatible = "qcom,seraph-debugcc";
		qcom,apsscc = <&apsscc>;
		qcom,camcc = <&camcc>;
		qcom,evacc = <&evacc>;
		qcom,gcc = <&gcc>;
		qcom,gpucc = <&gpucc>;
		qcom,gxclkctl = <&gxclkctldebugcc>;
		qcom,lsrcc = <&lsrcc>;
		qcom,videocc = <&videocc>;
		qcom,mccc = <&mccc>;
		clocks = <&rpmhcc RPMH_CXO_CLK>, <&camcc 0>,
			 <&evacc 0>, <&gcc 0>, <&gpucc 0>,
			 <&lsrcc 0>, <&videocc 0>;
		clock-names = "xo_clk_src", "camcc",
			      "evacc", "gcc", "gpucc",
			      "lsrcc", "videocc";
		#clock-cells = <1>;
	};

	cpufreq_hw: qcom,cpufreq-hw {
		compatible = "qcom,cpufreq-epss";
		reg = <0x17d91000 0x1000>, <0x17d92000 0x1000>;
		reg-names = "freq-domain0", "freq-domain1";
		clocks = <&rpmhcc RPMH_CXO_CLK>, <&gcc GCC_GPLL0>;
		clock-names = "xo", "alternate";
		interrupts = <GIC_SPI 30 IRQ_TYPE_LEVEL_HIGH>,
			<GIC_SPI 31 IRQ_TYPE_LEVEL_HIGH>;
		interrupt-names = "dcvsh0_int", "dcvsh1_int";
		#freq-domain-cells = <1>;
	};

	qcom,cpufreq-hw-debug {
		compatible = "qcom,cpufreq-hw-epss-debug";
		qcom,freq-hw-domain = <&cpufreq_hw 0>, <&cpufreq_hw 1>;
	};

	sdhc1_opp_table: sdhc1-opp-table {
		compatible = "operating-points-v2";

		opp-100000000 {
			opp-hz = /bits/ 64 <100000000>;
			opp-peak-kBps = <250000 133320>;
			opp-avg-kBps = <104000 0>;
		};

		opp-384000000 {
			opp-hz = /bits/ 64 <384000000>;
			opp-peak-kBps = <800000 300000>;
			opp-avg-kBps = <400000 0>;
		};
	};

	sdhc_1: sdhci@B24000 {
		status = "disabled";

		compatible = "qcom,sdhci-msm-v5";

		reg = <0x00B24000 0x1000>, <0x00B25000 0x1000>;
		reg-names = "hc", "cqhci";

		iommus = <&apps_smmu 0x120 0x0>;
		qcom,iommu-dma = "fastmap";

		/*
		 * iommu-dma-addr-pool- Indicate the range of data addresses which will be
		 * used in dma allocation.
		 *
		 * iommu-geometry -  This is specific for fastmap which Allow clients
		 * to save SMMU page table memory.
		 *
		 * The 2nd parameter indicates size of the smmu page table memory.
		 * If its exceeds beyond this size, last unused entry from page table
		 * memory will be invalidated.
		 *
		 * It's better to provide range of dma address, hence provide
		 * iommu-dma-addr-pool property along with iommu-geometry property.
		 */

		qcom,iommu-dma-addr-pool = <0x40000000 0x10000000>;
		qcom,iommu-geometry = <0x40000000 0x10000000>;

		interrupts = <GIC_SPI 150 IRQ_TYPE_LEVEL_HIGH>,
				<GIC_SPI 261 IRQ_TYPE_LEVEL_HIGH>;
		interrupt-names = "hc_irq", "pwr_irq";

		clocks = <&gcc GCC_SDCC1_APPS_CLK>,
			<&gcc GCC_SDCC1_AHB_CLK>,
			<&gcc GCC_SDCC1_ICE_CORE_CLK>;
		clock-names = "core", "iface", "ice_core";

		qcom,ice-clk-rates = <300000000 100000000>;

		interconnects = <&system_noc MASTER_SDCC_1 &mc_virt SLAVE_EBI1>,
			<&gem_noc MASTER_APPSS_PROC &cnoc_cfg SLAVE_SDCC_1>;
		interconnect-names = "sdhc-ddr","cpu-sdhc";
		operating-points-v2 = <&sdhc1_opp_table>;

	      /* DLL HSR settings. Refer go/hsr - <Target> DLL settings */
		qcom,dll-hsr-list = <0x000F44EC 0x0 0x01 0x290106C0 0x80040868>;

		cap-mmc-hw-reset;

		non-removable;
		supports-cqe;

		no-sd;
		no-sdio;

		bus-width = <8>;

		/* Add dt entry for gcc hw reset */
		resets = <&gcc GCC_SDCC1_BCR>;
		reset-names = "core_reset";

		qos0 {
			mask = <0x10>;
			vote = <44>;
		};

		qos1 {
			mask = <0x0f>;
			vote = <44>;
		};
	};

	thermal_zones: thermal-zones {};

	trust_ui_vm_vblk0_ring: trust_ui_vm_vblk0_ring {
		size = <0x4000>;
		gunyah-label = <0x11>;
	};

	trust_ui_vm_vblk1_ring: trust_ui_vm_vblk1_ring {
		size = <0x4000>;
		gunyah-label = <0x10>;
	};

	trust_ui_vm_swiotlb: trust_ui_vm_swiotlb {
		size = <0x100000>;
		gunyah-label = <0x12>;
	};

	trust_ui_vm: qcom,trust_ui_vm {
		vm_name = "trustedvm";
		shared-buffers-size = <0x108000>;
		shared-buffers = <&trust_ui_vm_vblk0_ring &trust_ui_vm_vblk1_ring &trust_ui_vm_swiotlb>;
	};

	trust_ui_vm_virt_be0: trust_ui_vm_virt_be0@11 {
		qcom,vm = <&trust_ui_vm>;
		qcom,label = <0x11>;
	};

	trust_ui_vm_virt_be1: trust_ui_vm_virt_be1@10 {
		qcom,vm = <&trust_ui_vm>;
		qcom,label = <0x10>;
	};

	gh_secure_vm_loader0: gh-secure-vm-loader@0 {
		compatible = "qcom,gh-secure-vm-loader";
		qcom,pas-id = <28>;
		qcom,vmid = <45>;
		qcom,firmware-name = "trustedvm";
		qcom,keep-running;
		memory-region = <&trust_ui_vm_region &vm_comm_mem>;
		virtio-backends = <&trust_ui_vm_virt_be0 &trust_ui_vm_virt_be1>;
	};

	gh-secure-vm-loader@2 {
		compatible = "qcom,gh-secure-vm-loader";
		qcom,pas-id = <35>;
		qcom,vmid = <50>;
		qcom,firmware-name = "cpusys_vm";
		memory-region = <&cpusys_vm_mem>;
		ext-region = <&chipinfo_mem>;
		ext-label = <0x7>;
	};

	spmi_bus: spmi0_bus: qcom,spmi@c42d000 {
		compatible = "qcom,spmi-pmic-arb";
		reg = <0xc42d000 0x4000>,
		      <0xc400000 0x3000>,
		      <0xc500000 0x400000>,
		      <0xc440000 0x80000>,
		      <0xc4c0000 0x10000>;
		reg-names = "cnfg", "core", "chnls", "obsrvr", "intr";
		interrupts-extended = <&pdc 1 IRQ_TYPE_LEVEL_HIGH>;
		interrupt-names = "periph_irq";
		interrupt-controller;
		#interrupt-cells = <4>;
		#address-cells = <2>;
		#size-cells = <0>;
		cell-index = <0>;
		qcom,channel = <0>;
		qcom,ee = <0>;
		qcom,bus-id = <0>;
	};

	spmi0_debug_bus: qcom,spmi-debug@11314000 {
		compatible = "qcom,spmi-pmic-arb-debug";
		reg = <0x11314000 0x60>, <0x221c8784 0x4>;
		reg-names = "core", "fuse";
		clock-names = "core_clk";
		qcom,fuse-enable-bit = <18>;
		#address-cells = <2>;
		#size-cells = <0>;
		depends-on-supply = <&spmi_bus>;

		qcom,pmar2230-debug@0 {
			compatible = "qcom,spmi-pmic";
			reg = <0 SPMI_USID>;
			#address-cells = <2>;
			#size-cells = <0>;
			qcom,can-sleep;
		};

		qcom,pmg1110-debug@a {
			compatible = "qcom,spmi-pmic";
			reg = <10 SPMI_USID>;
			#address-cells = <2>;
			#size-cells = <0>;
			qcom,can-sleep;
		};

		qcom,pm8010-debug@c {
			compatible = "qcom,spmi-pmic";
			reg = <12 SPMI_USID>;
			#address-cells = <2>;
			#size-cells = <0>;
			qcom,can-sleep;
		};

		qcom,pm8010-debug@d {
			compatible = "qcom,spmi-pmic";
			reg = <13 SPMI_USID>;
			#address-cells = <2>;
			#size-cells = <0>;
			qcom,can-sleep;
		};
	};
};

#include "pineapple-gdsc.dtsi"

&cam_cc_bps_gdsc {
	parent-supply = <&cam_cc_titan_top_gdsc>;
	clocks = <&gcc GCC_CAMERA_AHB_CLK>;
	clock-names = "ahb_clk";
	status = "ok";
};

&cam_cc_ife_0_gdsc {
	parent-supply = <&cam_cc_titan_top_gdsc>;
	clocks = <&gcc GCC_CAMERA_AHB_CLK>;
	clock-names = "ahb_clk";
	qcom,support-hw-trigger;
	status = "ok";
};

&cam_cc_ife_1_gdsc {
	parent-supply = <&cam_cc_titan_top_gdsc>;
	clocks = <&gcc GCC_CAMERA_AHB_CLK>;
	clock-names = "ahb_clk";
	qcom,support-hw-trigger;
	status = "ok";
};

&cam_cc_ife_lite_0_gdsc {
	parent-supply = <&cam_cc_titan_top_gdsc>;
	clocks = <&gcc GCC_CAMERA_AHB_CLK>;
	clock-names = "ahb_clk";
	status = "ok";
};

&cam_cc_ife_lite_1_gdsc {
	parent-supply = <&cam_cc_titan_top_gdsc>;
	clocks = <&gcc GCC_CAMERA_AHB_CLK>;
	clock-names = "ahb_clk";
	status = "ok";
};

&cam_cc_ife_lite_2_gdsc {
	parent-supply = <&cam_cc_titan_top_gdsc>;
	clocks = <&gcc GCC_CAMERA_AHB_CLK>;
	clock-names = "ahb_clk";
	status = "ok";
};

&cam_cc_ipe_0_gdsc {
	parent-supply = <&cam_cc_titan_top_gdsc>;
	clocks = <&gcc GCC_CAMERA_AHB_CLK>;
	clock-names = "ahb_clk";
	status = "ok";
};

&cam_cc_titan_top_gdsc {
	parent-supply = <&VDD_CX_LEVEL>;
	clocks = <&gcc GCC_CAMERA_AHB_CLK>;
	clock-names = "ahb_clk";
	interconnects = <&mmss_noc MASTER_CAMNOC_HF &mmss_noc SLAVE_MNOC_HF_MEM_NOC>;
	interconnect-names = "mmnoc";
	reg = <0xadf4028 0x4>;
	qcom,support-hw-trigger;
	status = "ok";
};

&eva_cc_mvs0_gdsc {
	parent-supply = <&eva_cc_mvs0c_gdsc>;
	clocks = <&gcc GCC_EVA_AHB_CLK>;
	clock-names = "ahb_clk";
	status = "ok";
};

&eva_cc_mvs0c_gdsc {
	parent-supply = <&VDD_MM_LEVEL>;
	clocks = <&gcc GCC_EVA_AHB_CLK>;
	clock-names = "ahb_clk";
	status = "ok";
};

&gcc_pcie_0_gdsc {
	parent-supply = <&VDD_CX_LEVEL>;
	status = "ok";
};

&gcc_pcie_0_phy_gdsc {
	parent-supply = <&VDD_MX_LEVEL>;
	status = "ok";
};

&gcc_pcie_1_gdsc {
	parent-supply = <&VDD_CX_LEVEL>;
	status = "ok";
};

&gcc_pcie_1_phy_gdsc {
	parent-supply = <&VDD_MX_LEVEL>;
	status = "ok";
};

&gcc_usb30_prim_gdsc {
	parent-supply = <&VDD_CX_LEVEL>;
	status = "ok";
};

&gcc_usb3_phy_gdsc {
	parent-supply = <&VDD_MX_LEVEL>;
	reg = <0x15000c 0x4>;
	status = "ok";
};

&gpu_cc_cx_gdsc_hw_ctrl {
	reg = <0x3d99094 0x4>;
};

&gpu_cc_cx_gdsc {
	reg = <0x3d99080 0x4>;
	clocks = <&gcc GCC_GPU_CFG_AHB_CLK>;
	clock-names = "ahb_clk";
	parent-supply = <&VDD_CX_LEVEL>;
	proxy-supply = <&gpu_cc_cx_gdsc>;
	qcom,proxy-consumer-enable;
	status = "ok";
};

&gx_clkctl_gx_gdsc {
	reg-supply = <&gpu_cc_cx_gdsc>;
	parent-supply = <&VDD_GFX_LEVEL>;
	status = "ok";
};

&lsr_cc_lsr_noc_gdsc {
	parent-supply = <&VDD_MM_LEVEL>;
	clocks = <&gcc GCC_LSR_AHB_CLK>;
	clock-names = "ahb_clk";
	status = "ok";
};

&lsr_cc_mvs0_gdsc {
	parent-supply = <&lsr_cc_mvs0c_gdsc>;
	clocks = <&gcc GCC_LSR_AHB_CLK>;
	clock-names = "ahb_clk";
	status = "ok";
};

&lsr_cc_mvs0c_gdsc {
	parent-supply = <&VDD_MM_LEVEL>;
	clocks = <&gcc GCC_LSR_AHB_CLK>;
	clock-names = "ahb_clk";
	status = "ok";
};

&video_cc_mvs0_gdsc {
	parent-supply = <&video_cc_mvs0c_gdsc>;
	reg = <0xaaf80a8 0x4>;
	clocks = <&gcc GCC_VIDEO_AHB_CLK>;
	clock-names = "ahb_clk";
	status = "ok";
};

&video_cc_mvs0_vpp0_gdsc {
	parent-supply = <&VDD_MM_LEVEL>;
	clocks = <&gcc GCC_VIDEO_AHB_CLK>;
	clock-names = "ahb_clk";
	status = "ok";
};

&video_cc_mvs0_vpp1_gdsc {
	parent-supply = <&VDD_MM_LEVEL>;
	clocks = <&gcc GCC_VIDEO_AHB_CLK>;
	clock-names = "ahb_clk";
	status = "ok";
};

&video_cc_mvs0c_gdsc {
	parent-supply = <&VDD_MM_LEVEL>;
	reg = <0xaaf814c 0x4>;
	clocks = <&gcc GCC_VIDEO_AHB_CLK>;
	clock-names = "ahb_clk";
	status = "ok";
};

#include "seraph-pinctrl.dtsi"
#include "seraph-qupv3.dtsi"
#include "ipcc-test-seraph.dtsi"

&qupv3_se11_2uart {
	status = "ok";
};

#include "seraph-stub-regulators.dtsi"

&reserved_memory {
	#address-cells = <2>;
	#size-cells = <2>;
	ranges;

	/* global autoconfigured region for contiguous allocations */
	system_cma: linux,cma {
		compatible = "shared-dma-pool";
		alloc-ranges = <0x0 0x00000000 0x0 0xffffffff>;
		reusable;
		alignment = <0x0 0x400000>;
		size = <0x0 0x2000000>;
		linux,cma-default;
	};

	adsp_mem_heap: adsp_heap_region {
		compatible = "shared-dma-pool";
		alloc-ranges = <0x0 0x00000000 0x0 0xffffffff>;
		reusable;
		alignment = <0x0 0x400000>;
		size = <0x0 0xC00000>;
	};

	/* cdsp eva shared memory */
	cdsp_eva_mem: cdsp_eva_region {
		compatible = "shared-dma-pool";
		alloc-ranges = <0x0 0x00000000 0x0 0xffffffff>;
		reusable;
		alignment = <0x0 0x400000>;
		size = <0x0 0x400000>;
	};

	qseecom_mem: qseecom_region {
		compatible = "shared-dma-pool";
		alloc-ranges = <0x0 0x00000000 0x0 0xffffffff>;
		reusable;
		alignment = <0x0 0x400000>;
		size = <0x0 0x1400000>;
	};

	non_secure_display_memory: non_secure_display_region {
		compatible = "shared-dma-pool";
		alloc-ranges = <0x0 0x00000000 0x0 0xffffffff>;
		reusable;
		alignment = <0x0 0x400000>;
		size = <0x0 0xa400000>;
	};

	qseecom_ta_mem: qseecom_ta_region {
		compatible = "shared-dma-pool";
		alloc-ranges = <0x0 0x00000000 0x0 0xffffffff>;
		reusable;
		alignment = <0x0 0x400000>;
		size = <0x0 0x1000000>;
	};
};

&firmware {
	qcom_scm {
		compatible = "qcom,scm";
	};

	qcom_smcinvoke {
		compatible = "qcom,smcinvoke";
	};

	qcom_mem_object {
		compatible = "qcom,mem-object";
	};

	qtee_shmbridge {
		compatible = "qcom,tee-shared-memory-bridge";
	};

	qcom,hdcp {
		compatible = "qcom,hdcp";
		qcom,use-smcinvoke = <1>;
	};
};


#include "seraph-reserved-memory.dtsi"
#include "seraph-dma-heaps.dtsi"
#include "seraph-coresight.dtsi"
#include "seraph-debug.dtsi"
#include "msm-arm-smmu-seraph.dtsi"
#include "seraph-usb.dtsi"
